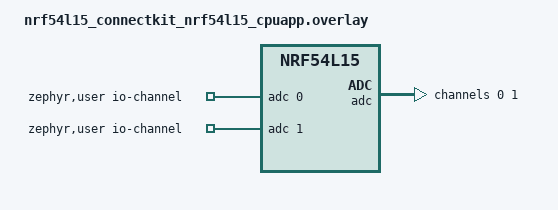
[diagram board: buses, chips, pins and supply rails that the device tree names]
/*
 * SPDX-License-Identifier: Apache-2.0
 *
 * Copyright (c) 2024 Nordic Semiconductor ASA
 * Copyright (c) 2016-2025, Makerdiary
 */

/ {
	zephyr,user {
		io-channels = <&adc 0>, <&adc 1>;
	};
};

&adc {
	#address-cells = <1>;
	#size-cells = <0>;

	channel@0 {
		reg = <0>;
		zephyr,gain = "ADC_GAIN_1_4";
		zephyr,reference = "ADC_REF_INTERNAL";
		zephyr,acquisition-time = <ADC_ACQ_TIME_DEFAULT>;
		zephyr,input-positive = <NRF_SAADC_AIN0>; /* P1.04 */
		zephyr,resolution = <10>;
	};

	channel@1 {
		reg = <1>;
		zephyr,gain = "ADC_GAIN_1_4";
		zephyr,reference = "ADC_REF_INTERNAL";
		zephyr,acquisition-time = <ADC_ACQ_TIME_DEFAULT>;
		zephyr,input-positive = <NRF_SAADC_VDD>;
		zephyr,resolution = <12>;
		zephyr,oversampling = <8>;
	};
};
